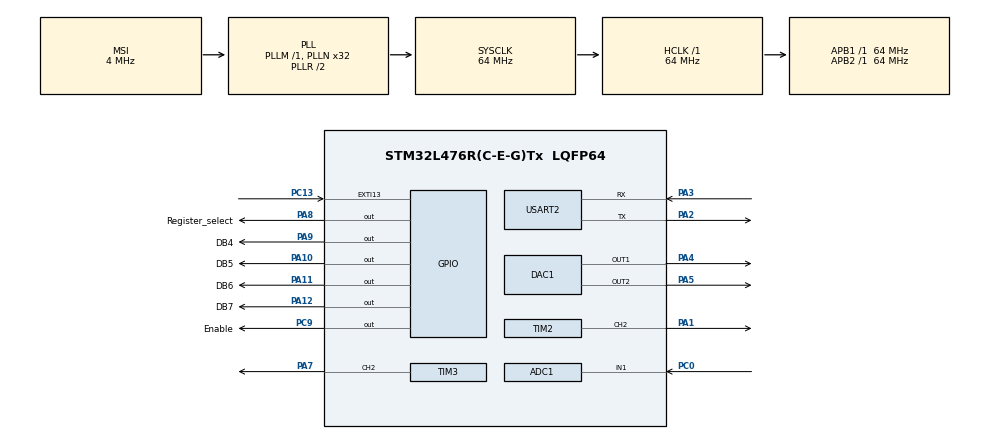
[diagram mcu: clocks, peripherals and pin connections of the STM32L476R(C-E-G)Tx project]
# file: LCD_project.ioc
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ADC1.Channel-0\#ChannelRegularConversion=ADC_CHANNEL_1
ADC1.ContinuousConvMode=ENABLE
ADC1.ExternalTrigConv=ADC_SOFTWARE_START
ADC1.NbrOfConversion=1
ADC1.NbrOfConversionFlag=1
ADC1.OffsetNumber-0\#ChannelRegularConversion=ADC_OFFSET_NONE
ADC1.Rank-0\#ChannelRegularConversion=1
ADC1.Resolution=ADC_RESOLUTION_12B
ADC1.SamplingTime-0\#ChannelRegularConversion=ADC_SAMPLETIME_12CYCLES_5
ADC1.master=1
CRC.CRCLength=CRC_POLYLENGTH_16B
CRC.DefaultPolynomialUse=DEFAULT_POLYNOMIAL_DISABLE
CRC.GeneratingPolynomial=X12+X5+X0
DAC1.DAC_Channel-DAC_OUT2=DAC_CHANNEL_2
Dma.Request0=USART2_RX
Dma.Request1=USART2_TX
Dma.USART2_RX.0.Direction=DMA_PERIPH_TO_MEMORY
Dma.USART2_RX.0.Instance=DMA1_Channel6
Dma.USART2_RX.0.MemDataAlignment=DMA_MDATAALIGN_BYTE
Dma.USART2_RX.0.MemInc=DMA_MINC_ENABLE
Dma.USART2_RX.0.Mode=DMA_NORMAL
Dma.USART2_RX.0.PeriphDataAlignment=DMA_PDATAALIGN_BYTE
Dma.USART2_RX.0.PeriphInc=DMA_PINC_DISABLE
Dma.USART2_RX.0.Priority=DMA_PRIORITY_LOW
Dma.USART2_TX.1.Direction=DMA_MEMORY_TO_PERIPH
Dma.USART2_TX.1.Instance=DMA1_Channel7
Dma.USART2_TX.1.MemDataAlignment=DMA_MDATAALIGN_BYTE
Dma.USART2_TX.1.MemInc=DMA_MINC_ENABLE
Dma.USART2_TX.1.Mode=DMA_NORMAL
Dma.USART2_TX.1.PeriphDataAlignment=DMA_PDATAALIGN_BYTE
Dma.USART2_TX.1.PeriphInc=DMA_PINC_DISABLE
Dma.USART2_TX.1.Priority=DMA_PRIORITY_LOW
Mcu.Family=STM32L4
Mcu.Name=STM32L476R(C-E-G)Tx
Mcu.Package=LQFP64
NVIC.ADC1_2_IRQn=true\:0\:0\:false\:false\:true\:true\:true
NVIC.DMA1_Channel6_IRQn=true\:0\:0\:false\:false\:true\:false\:true
NVIC.DMA1_Channel7_IRQn=true\:0\:0\:false\:false\:true\:false\:true
NVIC.EXTI15_10_IRQn=true\:0\:0\:false\:false\:true\:true\:true
NVIC.PriorityGroup=NVIC_PRIORITYGROUP_4
NVIC.TIM2_IRQn=true\:0\:0\:false\:false\:true\:true\:true
NVIC.TIM6_DAC_IRQn=true\:0\:0\:false\:false\:true\:true\:true
NVIC.TIM7_IRQn=true\:0\:0\:false\:false\:true\:true\:true
NVIC.USART2_IRQn=true\:0\:0\:false\:false\:true\:true\:true
PA1.Signal=S_TIM2_CH2
PA10.GPIO_Label=DB5
PA10.GPIO_PuPd=GPIO_PULLDOWN
PA10.Signal=GPIO_Output
PA11.GPIO_Label=DB6
PA11.GPIO_PuPd=GPIO_PULLDOWN
PA11.Signal=GPIO_Output
PA12.GPIO_Label=DB7
PA12.GPIO_PuPd=GPIO_PULLDOWN
PA12.Signal=GPIO_Output
PA2.Mode=Asynchronous
PA2.Signal=USART2_TX
PA3.Mode=Asynchronous
PA3.Signal=USART2_RX
PA4.Signal=COMP_DAC11_group
PA5.Signal=COMP_DAC12_group
PA7.Signal=S_TIM3_CH2
PA8.GPIO_Label=Register_select
PA8.GPIO_PuPd=GPIO_PULLDOWN
PA8.Signal=GPIO_Output
PA9.GPIO_Label=DB4
PA9.GPIO_PuPd=GPIO_PULLDOWN
PA9.Signal=GPIO_Output
PC0.Signal=ADCx_IN1
PC13.Signal=GPXTI13
PC14-OSC32_IN\ (PC14).Mode=LSE-External-Oscillator
PC14-OSC32_IN\ (PC14).Signal=RCC_OSC32_IN
PC15-OSC32_OUT\ (PC15).Mode=LSE-External-Oscillator
PC15-OSC32_OUT\ (PC15).Signal=RCC_OSC32_OUT
PC9.GPIO_Label=Enable
PC9.GPIO_PuPd=GPIO_PULLDOWN
PC9.Signal=GPIO_Output
ProjectManager.HeapSize=0x200
ProjectManager.StackSize=0x400
ProjectManager.TargetToolchain=MDK-ARM V5.32
RCC.ADCFreq_Value=16000000
RCC.AHBFreq_Value=64000000
RCC.APB1Freq_Value=64000000
RCC.APB1TimFreq_Value=64000000
RCC.APB2Freq_Value=64000000
RCC.APB2TimFreq_Value=64000000
RCC.CortexFreq_Value=64000000
RCC.HCLKFreq_Value=64000000
RCC.HSE_VALUE=8000000
RCC.HSI_VALUE=16000000
RCC.MSI_VALUE=4000000
RCC.PLLN=32
RCC.PLLSAI1N=16
RCC.PLLSAI1R=RCC_PLLR_DIV4
RCC.RTCClockSelection=RCC_RTCCLKSOURCE_LSE
RCC.SYSCLKFreq_VALUE=64000000
RCC.SYSCLKSource=RCC_SYSCLKSOURCE_PLLCLK
RCC.USBFreq_Value=32000000
RCC.VCOOutputFreq_Value=128000000
RTC.Date=1
RTC.Hours=0
RTC.Minutes=0
RTC.Month=RTC_MONTH_FEBRUARY
RTC.Seconds=0
RTC.SynchPrediv=255
RTC.WeekDay=RTC_WEEKDAY_FRIDAY
RTC.Year=0
SH.ADCx_IN1.0=ADC1_IN1,IN1-Single-Ended
SH.COMP_DAC11_group.0=DAC1_OUT1,DAC_OUT1
SH.COMP_DAC12_group.0=DAC1_OUT2,DAC_OUT2
SH.S_TIM2_CH2.0=TIM2_CH2,PWM Generation2 CH2
SH.S_TIM3_CH2.0=TIM3_CH2,PWM Generation2 CH2
TIM2.Channel-PWM\ Generation2\ CH2=TIM_CHANNEL_2
TIM2.Period=1000
TIM2.Prescaler=63
TIM3.Channel-PWM\ Generation2\ CH2=TIM_CHANNEL_2
TIM3.Period=3
TIM3.Prescaler=16
TIM3.Pulse-PWM\ Generation2\ CH2=2
TIM6.Period=49999
TIM6.Prescaler=63
TIM7.Period=9999
TIM7.Prescaler=6399
USART2.VirtualMode-Asynchronous=VM_ASYNC
VP_CRC_VS_CRC.Mode=CRC_Activate
VP_RNG_VS_RNG.Mode=RNG_Activate
VP_RTC_VS_RTC_Activate.Mode=RTC_Enabled
VP_RTC_VS_RTC_Calendar.Mode=RTC_Calendar
VP_TIM2_VS_ClockSourceINT.Mode=Internal
VP_TIM3_VS_ClockSourceINT.Mode=Internal
VP_TIM6_VS_ClockSourceINT.Mode=Enable_Timer
VP_TIM7_VS_ClockSourceINT.Mode=Enable_Timer
board=custom

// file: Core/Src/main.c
/* USER CODE BEGIN Header */
/**
  ******************************************************************************
  * @file           : main.c
  * @brief          : Main program body
  ******************************************************************************
  * @attention
  *
  * <h2><center>&copy; Copyright (c) 2023 STMicroelectronics.
  * All rights reserved.</center></h2>
  *
  * This software component is licensed by ST under BSD 3-Clause license,
  * the "License"; You may not use this file except in compliance with the
  * License. You may obtain a copy of the License at:
  *                        opensource.org/licenses/BSD-3-Clause
  *
  ******************************************************************************
  */
/* USER CODE END Header */
#include "main.h"

/* USER CODE BEGIN Includes */
#include "lcd.h"
#include "string.h"
#include "stdlib.h"
#include "stdio.h"
#include "FSA.h"
#include "Filter.h"
/* USER CODE END Includes */

ADC_HandleTypeDef hadc1;

CRC_HandleTypeDef hcrc;

DAC_HandleTypeDef hdac1;

RNG_HandleTypeDef hrng;

RTC_HandleTypeDef hrtc;

TIM_HandleTypeDef htim2;
TIM_HandleTypeDef htim3;
TIM_HandleTypeDef htim6;
TIM_HandleTypeDef htim7;

UART_HandleTypeDef huart2;
DMA_HandleTypeDef hdma_usart2_rx;
DMA_HandleTypeDef hdma_usart2_tx;

void SystemClock_Config(void);
void PeriphCommonClock_Config(void);
static void MX_GPIO_Init(void);
static void MX_ADC1_Init(void);
static void MX_TIM6_Init(void);
static void MX_DMA_Init(void);
static void MX_USART2_UART_Init(void);
static void MX_RTC_Init(void);
static void MX_RNG_Init(void);
static void MX_TIM2_Init(void);
static void MX_TIM3_Init(void);
static void MX_CRC_Init(void);
static void MX_TIM7_Init(void);
static void MX_DAC1_Init(void);

/* USER CODE BEGIN 0 */
//uint32_t adcValue;
//float voltage_float;
//char voltage_str[50];
//void HAL_ADC_ConvCpltCallback(ADC_HandleTypeDef* hadc)
//{
//	if(hadc->Instance == ADC1)
//	{
//		uint32_t adcValue = HAL_ADC_GetValue(&hadc1);
//		voltage_float = 3.3f * adcValue / 4096.0f;
//	}
//}

//void HAL_TIM_PeriodElapsedCallback(TIM_HandleTypeDef *htim)
//{
//	if(htim->Instance == TIM6)
//	{
//	  HAL_GPIO_TogglePin(GPIOA, GPIO_PIN_5);
//		sprintf(voltage_str,"Напряжение:%.2fВ\n",voltage_float);
//		HAL_UART_Transmit(&huart2, (uint8_t*)voltage_str, strlen(voltage_str),0xffff);
//		LCD_Set_Cursor(1,0);
//		LCD_Print_String(voltage_str);
//	}
//}
//void HAL_TIM_PeriodElapsedCallback(TIM_HandleTypeDef *htim)
//{
//	if(htim->Instance == TIM6)
//  {
//		static uint8_t flag = 0;
//		uint32_t brightness = __HAL_TIM_GET_COMPARE(&htim2,TIM_CHANNEL_2);
//		if(flag == 0)
//		{
//			brightness = brightness - 20;
//			if(brightness == 0)
//			{
//				flag = 1;
//			}
//		}
//		else
//		{
//			brightness = brightness + 20;
//			if(brightness == 1000)
//			{
//				flag = 0;
//			}
//		}
//		__HAL_TIM_SET_COMPARE(&htim2,TIM_CHANNEL_2,brightness);
//	}
//}
//char read_value[ARRAY_ELEMENTS];
//extern struct ring_buffer usart_recieve;
float signal_noise[COUNTS];
float signal_filtered[COUNTS];
/* USER CODE END 0 */

int main(void)
{
  /* USER CODE BEGIN 1 */
  make_noise(signal_noise,COUNTS);
	Filter(signal_noise,signal_filtered,COUNTS,WINDOW);
  /* USER CODE END 1 */

  /* MCU Configuration--------------------------------------------------------*/

  /* Reset of all peripherals, Initializes the Flash interface and the Systick. */
  HAL_Init();

  /* Configure the system clock */
  SystemClock_Config();

/* Configure the peripherals common clocks */
  PeriphCommonClock_Config();

  /* Initialize all configured peripherals */
  MX_GPIO_Init();
  MX_ADC1_Init();
  MX_TIM6_Init();
  MX_DMA_Init();
  MX_USART2_UART_Init();
  MX_RTC_Init();
  MX_RNG_Init();
  MX_TIM2_Init();
  MX_TIM3_Init();
  MX_CRC_Init();
  MX_TIM7_Init();
  MX_DAC1_Init();
  /* USER CODE BEGIN 2 */

	/*********************************ADC INIT****************************************/

//	NVIC_EnableIRQ(ADC1_IRQn); //глобальные прерывания
//	NVIC_SetPriority(ADC1_IRQn,0);
//	//тактирование
//	RCC->AHB2ENR |= RCC_AHB2ENR_ADCEN;
//	RCC->CR |= RCC_CR_PLLSAI1ON;
//	RCC->PLLSAI1CFGR |= RCC_PLLSAI1CFGR_PLLSAI1R_1;
//	RCC->PLLSAI1CFGR |= RCC_PLLSAI1CFGR_PLLSAI1N_1;
//	RCC->PLLSAI1CFGR |= RCC_PLLSAI1CFGR_PLLSAI1REN;
//	RCC->CCIPR |= RCC_CCIPR_ADCSEL_0;
//	//настройка порта
//	RCC->AHB2ENR |= RCC_AHB2ENR_GPIOCEN;
//	GPIOC->ASCR |= 0x01;
//	//включение
//	ADC1->CR &= ~ADC_CR_DEEPPWD; //выход из спящего режима
//	ADC1->CR |= ADC_CR_ADVREGEN; //подача питания
//	delay(0.05);
//	//калибровка
//	ADC1->CR &= ~ADC_CR_ADEN;
//	ADC1->CR &= ~ADC_CR_ADCALDIF;
//	ADC1->CR |= ADC_CR_ADCAL;
//	while((ADC1->CR & ADC_CR_ADCAL)!=0);
//	//настройка параметров
//	ADC1->CFGR |= ADC_CFGR_CONT; //Continuous Conversion Mode
//	ADC1->SMPR1 |= ADC_SMPR1_SMP1_1; //Sampling time 12.5 Cycles
//	ADC1->SQR1 |= ADC_SQR1_SQ1_0; //канал 1
//	//прерывания
//	ADC1->IER |= ADC_IER_OVRIE;
//	ADC1->IER |= ADC_IER_EOCIE;
//	//включение преобразований
//	ADC1->CR |= ADC_CR_ADEN;
//	delay(0.05);
//	ADC1->CR |= ADC_CR_ADSTART;

	/*********************************TIM INIT****************************************/

//	NVIC_EnableIRQ(TIM6_IRQn); //глобальные прерывания
//	NVIC_SetPriority(TIM6_IRQn,0);
//	//тактирование
//	RCC->APB1ENR1 |= RCC_APB1ENR1_TIM6EN;
//	//включение
//	TIM6->CR1 |= TIM_CR1_CEN;
//	//прерывания
//	TIM6->DIER |= TIM_DIER_UIE;
//	//настройка параметров
//	TIM6->PSC = 0x18ff;
//	TIM6->ARR = 0x2710;

	/********************************UART INIT****************************************/

//	NVIC_EnableIRQ(USART2_IRQn); //глобальные прерывания
//	NVIC_SetPriority(USART2_IRQn,0);
//	//тактирование
//	RCC->APB1ENR1 |= RCC_APB1ENR1_USART2EN;
//	//настройка портов
//	RCC->AHB2ENR |= RCC_AHB2ENR_GPIOAEN;
//	GPIOA->MODER &= ~GPIO_MODER_MODER2;
//	GPIOA->MODER &= ~GPIO_MODER_MODER3;
//	GPIOA->MODER |= GPIO_MODER_MODER2_1 | GPIO_MODER_MODER3_1;
//	GPIOA->OSPEEDR |= GPIO_OSPEEDR_OSPEED2 | GPIO_OSPEEDR_OSPEED3;
//	GPIOA->AFR[0] = (GPIO_AFRL_AFSEL2_3 - 0x100) | (GPIO_AFRL_AFSEL3_3 - 0x1000);
//	//включение
//	USART2->CR1 |= USART_CR1_UE;
//	//настройка параметров
//	USART2->BRR = 0x22c; //Baud rate
//	USART2->CR1 |= USART_CR1_TE;
//	USART2->CR1 |= USART_CR1_RE;
	//прерывания по приёму
	USART2->CR1 |= USART_CR1_RXNEIE;

	/*********************************************************************************/

//	LCD_init();
//	LCD_Cursor_On_Off(0);
//	HAL_TIM_Base_Start_IT(&htim6);
//	HAL_TIM_Base_Start_IT(&htim7);
//	HAL_TIM_PWM_Start(&htim2,TIM_CHANNEL_2);
//	HAL_TIM_PWM_Start(&htim3,TIM_CHANNEL_2);
//	LCD_Print_String("Торговый автомат");
//	LCD_Set_Cursor(2,0);
//	LCD_Print_String(" Цена шок. 20р.");
//	LCD_Set_Cursor(1,0);
	//HAL_ADC_Start_IT(&hadc1);
	HAL_DAC_Start(&hdac1,DAC_CHANNEL_1);
	HAL_DAC_Start(&hdac1,DAC_CHANNEL_2);
  /* USER CODE END 2 */

  /* Infinite loop */
  /* USER CODE BEGIN WHILE */
  while (1)
  {
		//transmit_to_USART(signal_noise,signal_filtered,COUNTS);
		//LCD_blink();
		//clock();
    //random_print();
		//read_from_ringbuffer(read_value,&usart_recieve);
    /* USER CODE END WHILE */

  }
}

void SystemClock_Config(void)
{
  RCC_OscInitTypeDef RCC_OscInitStruct = {0};
  RCC_ClkInitTypeDef RCC_ClkInitStruct = {0};

  /** Configure the main internal regulator output voltage
  */
  if (HAL_PWREx_ControlVoltageScaling(PWR_REGULATOR_VOLTAGE_SCALE1) != HAL_OK)
  {
    Error_Handler();
  }
  /** Configure LSE Drive Capability
  */
  HAL_PWR_EnableBkUpAccess();
  __HAL_RCC_LSEDRIVE_CONFIG(RCC_LSEDRIVE_LOW);
  /** Initializes the RCC Oscillators according to the specified parameters
  * in the RCC_OscInitTypeDef structure.
  */
  RCC_OscInitStruct.OscillatorType = RCC_OSCILLATORTYPE_LSE|RCC_OSCILLATORTYPE_MSI;
  RCC_OscInitStruct.LSEState = RCC_LSE_ON;
  RCC_OscInitStruct.MSIState = RCC_MSI_ON;
  RCC_OscInitStruct.MSICalibrationValue = 0;
  RCC_OscInitStruct.MSIClockRange = RCC_MSIRANGE_6;
  RCC_OscInitStruct.PLL.PLLState = RCC_PLL_ON;
  RCC_OscInitStruct.PLL.PLLSource = RCC_PLLSOURCE_MSI;
  RCC_OscInitStruct.PLL.PLLM = 1;
  RCC_OscInitStruct.PLL.PLLN = 32;
  RCC_OscInitStruct.PLL.PLLP = RCC_PLLP_DIV7;
  RCC_OscInitStruct.PLL.PLLQ = RCC_PLLQ_DIV2;
  RCC_OscInitStruct.PLL.PLLR = RCC_PLLR_DIV2;
  if (HAL_RCC_OscConfig(&RCC_OscInitStruct) != HAL_OK)
  {
    Error_Handler();
  }
  /** Initializes the CPU, AHB and APB buses clocks
  */
  RCC_ClkInitStruct.ClockType = RCC_CLOCKTYPE_HCLK|RCC_CLOCKTYPE_SYSCLK
                              |RCC_CLOCKTYPE_PCLK1|RCC_CLOCKTYPE_PCLK2;
  RCC_ClkInitStruct.SYSCLKSource = RCC_SYSCLKSOURCE_PLLCLK;
  RCC_ClkInitStruct.AHBCLKDivider = RCC_SYSCLK_DIV1;
  RCC_ClkInitStruct.APB1CLKDivider = RCC_HCLK_DIV1;
  RCC_ClkInitStruct.APB2CLKDivider = RCC_HCLK_DIV1;

  if (HAL_RCC_ClockConfig(&RCC_ClkInitStruct, FLASH_LATENCY_3) != HAL_OK)
  {
    Error_Handler();
  }
  /** Enable MSI Auto calibration
  */
  HAL_RCCEx_EnableMSIPLLMode();
}

void PeriphCommonClock_Config(void)
{
  RCC_PeriphCLKInitTypeDef PeriphClkInit = {0};

  /** Initializes the peripherals clock
  */
  PeriphClkInit.PeriphClockSelection = RCC_PERIPHCLK_RNG|RCC_PERIPHCLK_ADC;
  PeriphClkInit.AdcClockSelection = RCC_ADCCLKSOURCE_PLLSAI1;
  PeriphClkInit.RngClockSelection = RCC_RNGCLKSOURCE_PLLSAI1;
  PeriphClkInit.PLLSAI1.PLLSAI1Source = RCC_PLLSOURCE_MSI;
  PeriphClkInit.PLLSAI1.PLLSAI1M = 1;
  PeriphClkInit.PLLSAI1.PLLSAI1N = 16;
  PeriphClkInit.PLLSAI1.PLLSAI1P = RCC_PLLP_DIV7;
  PeriphClkInit.PLLSAI1.PLLSAI1Q = RCC_PLLQ_DIV2;
  PeriphClkInit.PLLSAI1.PLLSAI1R = RCC_PLLR_DIV4;
  PeriphClkInit.PLLSAI1.PLLSAI1ClockOut = RCC_PLLSAI1_48M2CLK|RCC_PLLSAI1_ADC1CLK;
  if (HAL_RCCEx_PeriphCLKConfig(&PeriphClkInit) != HAL_OK)
  {
    Error_Handler();
  }
}

static void MX_ADC1_Init(void)
{

  ADC_MultiModeTypeDef multimode = {0};
  ADC_ChannelConfTypeDef sConfig = {0};

  /** Common config
  */
  hadc1.Instance = ADC1;
  hadc1.Init.ClockPrescaler = ADC_CLOCK_ASYNC_DIV1;
  hadc1.Init.Resolution = ADC_RESOLUTION_12B;
  hadc1.Init.DataAlign = ADC_DATAALIGN_RIGHT;
  hadc1.Init.ScanConvMode = ADC_SCAN_DISABLE;
  hadc1.Init.EOCSelection = ADC_EOC_SINGLE_CONV;
  hadc1.Init.LowPowerAutoWait = DISABLE;
  hadc1.Init.ContinuousConvMode = ENABLE;
  hadc1.Init.NbrOfConversion = 1;
  hadc1.Init.DiscontinuousConvMode = DISABLE;
  hadc1.Init.ExternalTrigConv = ADC_SOFTWARE_START;
  hadc1.Init.ExternalTrigConvEdge = ADC_EXTERNALTRIGCONVEDGE_NONE;
  hadc1.Init.DMAContinuousRequests = DISABLE;
  hadc1.Init.Overrun = ADC_OVR_DATA_PRESERVED;
  hadc1.Init.OversamplingMode = DISABLE;
  if (HAL_ADC_Init(&hadc1) != HAL_OK)
  {
    Error_Handler();
  }
  /** Configure the ADC multi-mode
  */
  multimode.Mode = ADC_MODE_INDEPENDENT;
  if (HAL_ADCEx_MultiModeConfigChannel(&hadc1, &multimode) != HAL_OK)
  {
    Error_Handler();
  }
  /** Configure Regular Channel
  */
  sConfig.Channel = ADC_CHANNEL_1;
  sConfig.Rank = ADC_REGULAR_RANK_1;
  sConfig.SamplingTime = ADC_SAMPLETIME_12CYCLES_5;
  sConfig.SingleDiff = ADC_SINGLE_ENDED;
  sConfig.OffsetNumber = ADC_OFFSET_NONE;
  sConfig.Offset = 0;
  if (HAL_ADC_ConfigChannel(&hadc1, &sConfig) != HAL_OK)
  {
    Error_Handler();
  }

}

static void MX_CRC_Init(void)
{

  hcrc.Instance = CRC;
  hcrc.Init.DefaultPolynomialUse = DEFAULT_POLYNOMIAL_DISABLE;
  hcrc.Init.DefaultInitValueUse = DEFAULT_INIT_VALUE_ENABLE;
  hcrc.Init.GeneratingPolynomial = 4129;
  hcrc.Init.CRCLength = CRC_POLYLENGTH_16B;
  hcrc.Init.InputDataInversionMode = CRC_INPUTDATA_INVERSION_NONE;
  hcrc.Init.OutputDataInversionMode = CRC_OUTPUTDATA_INVERSION_DISABLE;
  hcrc.InputDataFormat = CRC_INPUTDATA_FORMAT_BYTES;
  if (HAL_CRC_Init(&hcrc) != HAL_OK)
  {
    Error_Handler();
  }

}

static void MX_DAC1_Init(void)
{

  DAC_ChannelConfTypeDef sConfig = {0};

  /** DAC Initialization
  */
  hdac1.Instance = DAC1;
  if (HAL_DAC_Init(&hdac1) != HAL_OK)
  {
    Error_Handler();
  }
  /** DAC channel OUT1 config
  */
  sConfig.DAC_SampleAndHold = DAC_SAMPLEANDHOLD_DISABLE;
  sConfig.DAC_Trigger = DAC_TRIGGER_NONE;
  sConfig.DAC_OutputBuffer = DAC_OUTPUTBUFFER_ENABLE;
  sConfig.DAC_ConnectOnChipPeripheral = DAC_CHIPCONNECT_DISABLE;
  sConfig.DAC_UserTrimming = DAC_TRIMMING_FACTORY;
  if (HAL_DAC_ConfigChannel(&hdac1, &sConfig, DAC_CHANNEL_1) != HAL_OK)
  {
    Error_Handler();
  }
  /** DAC channel OUT2 config
  */
  if (HAL_DAC_ConfigChannel(&hdac1, &sConfig, DAC_CHANNEL_2) != HAL_OK)
  {
    Error_Handler();
  }

}

static void MX_RNG_Init(void)
{

  hrng.Instance = RNG;
  if (HAL_RNG_Init(&hrng) != HAL_OK)
  {
    Error_Handler();
  }

}

static void MX_RTC_Init(void)
{

  RTC_TimeTypeDef sTime = {0};
  RTC_DateTypeDef sDate = {0};

  /** Initialize RTC Only
  */
  hrtc.Instance = RTC;
  hrtc.Init.HourFormat = RTC_HOURFORMAT_24;
  hrtc.Init.AsynchPrediv = 127;
  hrtc.Init.SynchPrediv = 255;
  hrtc.Init.OutPut = RTC_OUTPUT_DISABLE;
  hrtc.Init.OutPutRemap = RTC_OUTPUT_REMAP_NONE;
  hrtc.Init.OutPutPolarity = RTC_OUTPUT_POLARITY_HIGH;
  hrtc.Init.OutPutType = RTC_OUTPUT_TYPE_OPENDRAIN;
  if (HAL_RTC_Init(&hrtc) != HAL_OK)
  {
    Error_Handler();
  }

  /** Initialize RTC and set the Time and Date
  */
  sTime.Hours = 0x0;
  sTime.Minutes = 0x0;
  sTime.Seconds = 0x0;
  sTime.DayLightSaving = RTC_DAYLIGHTSAVING_NONE;
  sTime.StoreOperation = RTC_STOREOPERATION_RESET;
  if (HAL_RTC_SetTime(&hrtc, &sTime, RTC_FORMAT_BCD) != HAL_OK)
  {
    Error_Handler();
  }
  sDate.WeekDay = RTC_WEEKDAY_FRIDAY;
  sDate.Month = RTC_MONTH_FEBRUARY;
  sDate.Date = 0x1;
  sDate.Year = 0x0;

  if (HAL_RTC_SetDate(&hrtc, &sDate, RTC_FORMAT_BCD) != HAL_OK)
  {
    Error_Handler();
  }

}

static void MX_TIM2_Init(void)
{

  TIM_ClockConfigTypeDef sClockSourceConfig = {0};
  TIM_MasterConfigTypeDef sMasterConfig = {0};
  TIM_OC_InitTypeDef sConfigOC = {0};

  htim2.Instance = TIM2;
  htim2.Init.Prescaler = 63;
  htim2.Init.CounterMode = TIM_COUNTERMODE_UP;
  htim2.Init.Period = 1000;
  htim2.Init.ClockDivision = TIM_CLOCKDIVISION_DIV1;
  htim2.Init.AutoReloadPreload = TIM_AUTORELOAD_PRELOAD_DISABLE;
  if (HAL_TIM_Base_Init(&htim2) != HAL_OK)
  {
    Error_Handler();
  }
  sClockSourceConfig.ClockSource = TIM_CLOCKSOURCE_INTERNAL;
  if (HAL_TIM_ConfigClockSource(&htim2, &sClockSourceConfig) != HAL_OK)
  {
    Error_Handler();
  }
  if (HAL_TIM_PWM_Init(&htim2) != HAL_OK)
  {
    Error_Handler();
  }
  sMasterConfig.MasterOutputTrigger = TIM_TRGO_RESET;
  sMasterConfig.MasterSlaveMode = TIM_MASTERSLAVEMODE_DISABLE;
  if (HAL_TIMEx_MasterConfigSynchronization(&htim2, &sMasterConfig) != HAL_OK)
  {
    Error_Handler();
  }
  sConfigOC.OCMode = TIM_OCMODE_PWM1;
  sConfigOC.Pulse = 0;
  sConfigOC.OCPolarity = TIM_OCPOLARITY_HIGH;
  sConfigOC.OCFastMode = TIM_OCFAST_DISABLE;
  if (HAL_TIM_PWM_ConfigChannel(&htim2, &sConfigOC, TIM_CHANNEL_2) != HAL_OK)
  {
    Error_Handler();
  }
  HAL_TIM_MspPostInit(&htim2);

}

static void MX_TIM3_Init(void)
{

  TIM_ClockConfigTypeDef sClockSourceConfig = {0};
  TIM_MasterConfigTypeDef sMasterConfig = {0};
  TIM_OC_InitTypeDef sConfigOC = {0};

  htim3.Instance = TIM3;
  htim3.Init.Prescaler = 16;
  htim3.Init.CounterMode = TIM_COUNTERMODE_UP;
  htim3.Init.Period = 3;
  htim3.Init.ClockDivision = TIM_CLOCKDIVISION_DIV1;
  htim3.Init.AutoReloadPreload = TIM_AUTORELOAD_PRELOAD_DISABLE;
  if (HAL_TIM_Base_Init(&htim3) != HAL_OK)
  {
    Error_Handler();
  }
  sClockSourceConfig.ClockSource = TIM_CLOCKSOURCE_INTERNAL;
  if (HAL_TIM_ConfigClockSource(&htim3, &sClockSourceConfig) != HAL_OK)
  {
    Error_Handler();
  }
  if (HAL_TIM_PWM_Init(&htim3) != HAL_OK)
  {
    Error_Handler();
  }
  sMasterConfig.MasterOutputTrigger = TIM_TRGO_RESET;
  sMasterConfig.MasterSlaveMode = TIM_MASTERSLAVEMODE_DISABLE;
  if (HAL_TIMEx_MasterConfigSynchronization(&htim3, &sMasterConfig) != HAL_OK)
  {
    Error_Handler();
  }
  sConfigOC.OCMode = TIM_OCMODE_PWM1;
  sConfigOC.Pulse = 2;
  sConfigOC.OCPolarity = TIM_OCPOLARITY_HIGH;
  sConfigOC.OCFastMode = TIM_OCFAST_DISABLE;
  if (HAL_TIM_PWM_ConfigChannel(&htim3, &sConfigOC, TIM_CHANNEL_2) != HAL_OK)
  {
    Error_Handler();
  }
  HAL_TIM_MspPostInit(&htim3);

}

static void MX_TIM6_Init(void)
{

  TIM_MasterConfigTypeDef sMasterConfig = {0};

  htim6.Instance = TIM6;
  htim6.Init.Prescaler = 63;
  htim6.Init.CounterMode = TIM_COUNTERMODE_UP;
  htim6.Init.Period = 49999;
  htim6.Init.AutoReloadPreload = TIM_AUTORELOAD_PRELOAD_DISABLE;
  if (HAL_TIM_Base_Init(&htim6) != HAL_OK)
  {
    Error_Handler();
  }
  sMasterConfig.MasterOutputTrigger = TIM_TRGO_RESET;
  sMasterConfig.MasterSlaveMode = TIM_MASTERSLAVEMODE_DISABLE;
  if (HAL_TIMEx_MasterConfigSynchronization(&htim6, &sMasterConfig) != HAL_OK)
  {
    Error_Handler();
  }

}

static void MX_TIM7_Init(void)
{

  TIM_MasterConfigTypeDef sMasterConfig = {0};

  htim7.Instance = TIM7;
  htim7.Init.Prescaler = 6399;
  htim7.Init.CounterMode = TIM_COUNTERMODE_UP;
  htim7.Init.Period = 9999;
  htim7.Init.AutoReloadPreload = TIM_AUTORELOAD_PRELOAD_DISABLE;
  if (HAL_TIM_Base_Init(&htim7) != HAL_OK)
  {
    Error_Handler();
  }
  sMasterConfig.MasterOutputTrigger = TIM_TRGO_RESET;
  sMasterConfig.MasterSlaveMode = TIM_MASTERSLAVEMODE_DISABLE;
  if (HAL_TIMEx_MasterConfigSynchronization(&htim7, &sMasterConfig) != HAL_OK)
  {
    Error_Handler();
  }

}

static void MX_USART2_UART_Init(void)
{

  huart2.Instance = USART2;
  huart2.Init.BaudRate = 115200;
  huart2.Init.WordLength = UART_WORDLENGTH_8B;
  huart2.Init.StopBits = UART_STOPBITS_1;
  huart2.Init.Parity = UART_PARITY_NONE;
  huart2.Init.Mode = UART_MODE_TX_RX;
  huart2.Init.HwFlowCtl = UART_HWCONTROL_NONE;
  huart2.Init.OverSampling = UART_OVERSAMPLING_16;
  huart2.Init.OneBitSampling = UART_ONE_BIT_SAMPLE_DISABLE;
  huart2.AdvancedInit.AdvFeatureInit = UART_ADVFEATURE_NO_INIT;
  if (HAL_UART_Init(&huart2) != HAL_OK)
  {
    Error_Handler();
  }

}

static void MX_DMA_Init(void)
{

  /* DMA controller clock enable */
  __HAL_RCC_DMA1_CLK_ENABLE();

  /* DMA interrupt init */
  /* DMA1_Channel6_IRQn interrupt configuration */
  HAL_NVIC_SetPriority(DMA1_Channel6_IRQn, 0, 0);
  HAL_NVIC_EnableIRQ(DMA1_Channel6_IRQn);
  /* DMA1_Channel7_IRQn interrupt configuration */
  HAL_NVIC_SetPriority(DMA1_Channel7_IRQn, 0, 0);
  HAL_NVIC_EnableIRQ(DMA1_Channel7_IRQn);

}

static void MX_GPIO_Init(void)
{
  GPIO_InitTypeDef GPIO_InitStruct = {0};

  /* GPIO Ports Clock Enable */
  __HAL_RCC_GPIOC_CLK_ENABLE();
  __HAL_RCC_GPIOA_CLK_ENABLE();

  /*Configure GPIO pin Output Level */
  HAL_GPIO_WritePin(Enable_GPIO_Port, Enable_Pin, GPIO_PIN_RESET);

  /*Configure GPIO pin Output Level */
  HAL_GPIO_WritePin(GPIOA, Register_select_Pin|DB4_Pin|DB5_Pin|DB6_Pin
                          |DB7_Pin, GPIO_PIN_RESET);

  /*Configure GPIO pin : PC13 */
  GPIO_InitStruct.Pin = GPIO_PIN_13;
  GPIO_InitStruct.Mode = GPIO_MODE_IT_RISING;
  GPIO_InitStruct.Pull = GPIO_NOPULL;
  HAL_GPIO_Init(GPIOC, &GPIO_InitStruct);

  /*Configure GPIO pin : Enable_Pin */
  GPIO_InitStruct.Pin = Enable_Pin;
  GPIO_InitStruct.Mode = GPIO_MODE_OUTPUT_PP;
  GPIO_InitStruct.Pull = GPIO_PULLDOWN;
  GPIO_InitStruct.Speed = GPIO_SPEED_FREQ_LOW;
  HAL_GPIO_Init(Enable_GPIO_Port, &GPIO_InitStruct);

  /*Configure GPIO pins : Register_select_Pin DB4_Pin DB5_Pin DB6_Pin
                           DB7_Pin */
  GPIO_InitStruct.Pin = Register_select_Pin|DB4_Pin|DB5_Pin|DB6_Pin
                          |DB7_Pin;
  GPIO_InitStruct.Mode = GPIO_MODE_OUTPUT_PP;
  GPIO_InitStruct.Pull = GPIO_PULLDOWN;
  GPIO_InitStruct.Speed = GPIO_SPEED_FREQ_LOW;
  HAL_GPIO_Init(GPIOA, &GPIO_InitStruct);

  /* EXTI interrupt init*/
  HAL_NVIC_SetPriority(EXTI15_10_IRQn, 0, 0);
  HAL_NVIC_EnableIRQ(EXTI15_10_IRQn);

}

void Error_Handler(void)
{
  __disable_irq();
  while (1)
  {
  }
}

/************************ (C) COPYRIGHT STMicroelectronics *****END OF FILE****/
